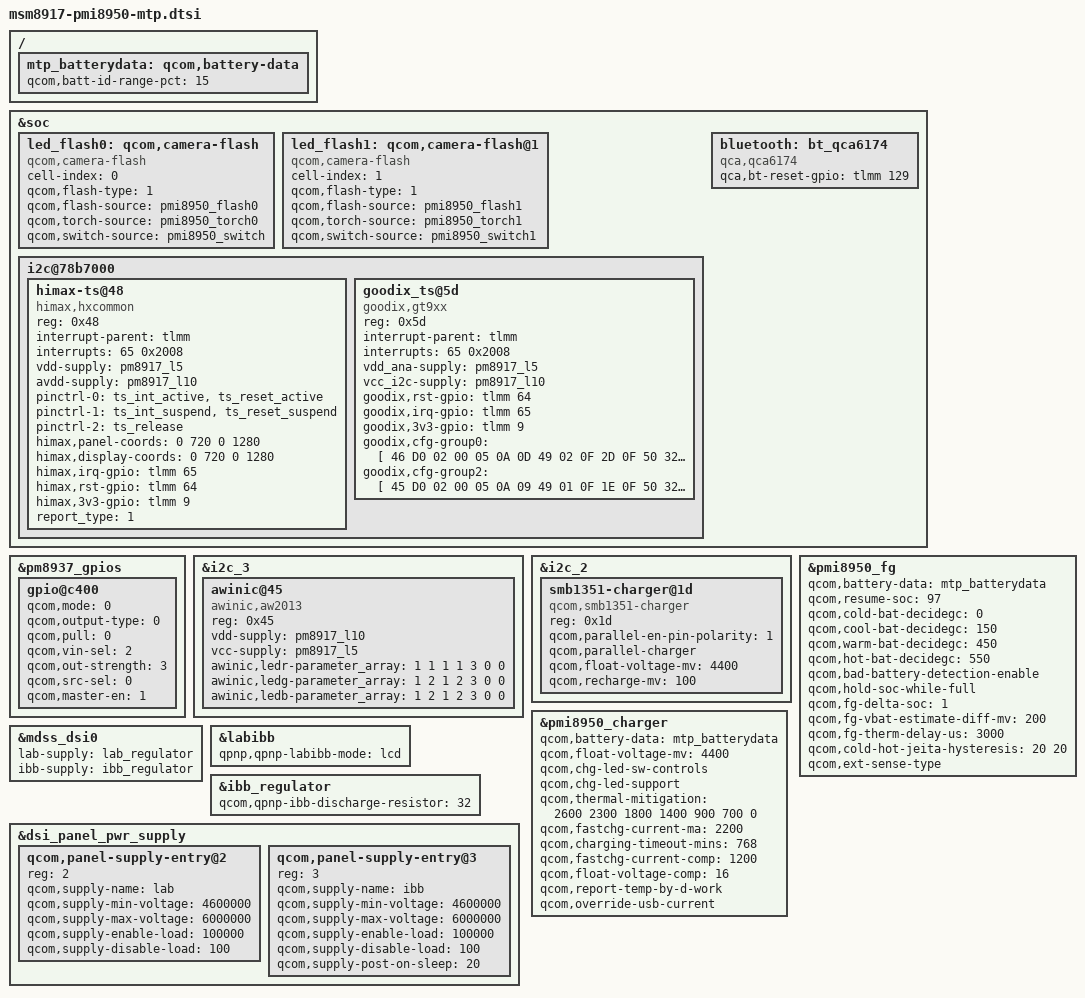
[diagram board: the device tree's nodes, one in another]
/*
 * Copyright (c) 2015-2017, The Linux Foundation. All rights reserved.
 *
 * This program is free software; you can redistribute it and/or modify
 * it under the terms of the GNU General Public License version 2 and
 * only version 2 as published by the Free Software Foundation.
 *
 * This program is distributed in the hope that it will be useful,
 * but WITHOUT ANY WARRANTY; without even the implied warranty of
 * MERCHANTABILITY or FITNESS FOR A PARTICULAR PURPOSE.  See the
 * GNU General Public License for more details.
 */

#include "msm-pmi8950.dtsi"
#include "msm8917-mtp.dtsi"
#include "msm8917-audio-mtp.dtsi"

&soc {
	led_flash0: qcom,camera-flash {
		cell-index = <0>;
		compatible = "qcom,camera-flash";
		qcom,flash-type = <1>;
		qcom,flash-source = <&pmi8950_flash0>;
		qcom,torch-source = <&pmi8950_torch0>;
		qcom,switch-source = <&pmi8950_switch>;
	};

    led_flash1: qcom,camera-flash@1 {
        cell-index = <1>;
        compatible = "qcom,camera-flash";
        qcom,flash-type = <1>;
        qcom,flash-source = <&pmi8950_flash1>;
        qcom,torch-source = <&pmi8950_torch1>;
        qcom,switch-source = <&pmi8950_switch1>;
    };

	i2c@78b7000 {
		status = "ok";
		himax-ts@48 {
			compatible = "himax,hxcommon";
			reg = <0x48>;
			interrupt-parent = <&tlmm>;
			interrupts = <65 0x2008>;
			vdd-supply = <&pm8917_l5>;
			avdd-supply = <&pm8917_l10>;
			pinctrl-names = "pmx_ts_active","pmx_ts_suspend",
				"pmx_ts_release";
			pinctrl-0 = <&ts_int_active &ts_reset_active>;
			pinctrl-1 = <&ts_int_suspend &ts_reset_suspend>;
			pinctrl-2 = <&ts_release>;
			himax,panel-coords   	= <0 720 0 1280>;
			himax,display-coords 	= <0 720 0 1280>;
			himax,irq-gpio       	= <&tlmm 65 0x00>;
			himax,rst-gpio       	= <&tlmm 64 0x00>;
			himax,3v3-gpio      	= <&tlmm 9 0x00>;
			report_type             = <1>;
		};
		goodix_ts@5d {
			compatible = "goodix,gt9xx";
			reg = <0x5d>;
			interrupt-parent = <&tlmm>;
			interrupts = <65 0x2008>;
			vdd_ana-supply = <&pm8917_l5>;
			vcc_i2c-supply = <&pm8917_l10>;
			goodix,rst-gpio = <&tlmm 64 0x00>;
			goodix,irq-gpio = <&tlmm 65 0x00>;
			goodix,3v3-gpio = <&tlmm 9 0x00>;
			goodix,cfg-group0 = [
				46 D0 02 00 05 0A 0D 49 02 0F
				2D 0F 50 32 03 00 00 00 00 00
				00 00 04 18 18 20 14 87 27 CD
				40 3E 09 06 BB 0A 01 1B 33 11
				05 32 0A 03 32 00 40 32 FA A0
				43 28 5A 85 C0 C5 01 1E 00 04
				B0 2B 00 97 33 00 83 3C 00 73
				46 00 64 53 00 64 18 38 60 00
				F0 50 50 FF FF 17 00 91 09 03
				61 6B 03 50 FF 67 00 33 00 28
				00 00 00 00 00 01 50 57 61 03
				50 28 00 01 02 03 04 05 06 07
				08 09 0A 0B 18 17 16 15 14 13
				12 11 10 0F 0E 0D 0C FF FF FF
				FF FF 29 28 24 22 20 1F 1E 0A
				08 06 05 04 02 00 FF FF FF 00
				00 00 00 00 00 00 00 00 00 00
				00 00 00 00 07 00 00 00 88 20
				02 00 00 00 00 00 00 00 00 00
				28 50 00 00 00 00 00 00 00 00
				00 00 00 00 00 00 00 00 00 00
				00 00 00 00 00 00 00 00 00 00
				00 00 00 00 00 00 B6 01];
			goodix,cfg-group2 = [
				45 D0 02 00 05 0A 09 49 01 0F 
				1E 0F 50 32 03 00 00 00 00 00 
				00 00 04 18 18 20 14 87 27 CD 
				69 67 97 05 BB 0A 00 1A 33 11 
				05 32 0A 03 32 00 00 32 FA A0 
				43 4B 7D 85 C0 C5 01 1E 00 04 
				A0 4F 00 93 57 00 87 60 00 7C 
				6B 00 72 76 00 72 18 38 60 00 
				F0 50 50 FF FF 17 00 91 02 03 
				61 6B 03 50 FF 67 00 33 00 28 
				00 00 00 00 00 01 50 57 61 03 
				50 28 00 01 02 03 04 05 06 07 
				08 09 0A 0B 18 17 16 15 14 13 
				12 11 10 0F 0E 0D 0C FF FF FF 
				FF FF 29 28 24 22 20 1F 1E 0A 
				08 06 05 04 02 00 FF FF FF 00 
				00 00 00 00 00 00 00 00 00 00 
				00 00 00 00 07 00 00 00 88 20 
				02 00 00 00 00 00 00 00 00 00 
				00 00 00 00 00 00 00 00 00 00 
				00 00 00 00 00 00 00 00 00 00 
				00 00 00 00 00 00 00 00 00 00 
				00 00 00 00 00 00 9E 01]; 
		};
	};
	
	bluetooth: bt_qca6174 {
		compatible = "qca,qca6174";
		qca,bt-reset-gpio = <&tlmm 129 0>; /* BT_EN */
	};
};

/{
	mtp_batterydata: qcom,battery-data {
		qcom,batt-id-range-pct = <15>;
		#include "batterydata-qrd-veken-4v4-3000mah.dtsi"
		#include "batterydata-qrd-jiade-4v4-3000mah.dtsi"
	};
};

&pm8937_gpios {
	gpio@c400 {
		qcom,mode = <0>;
		qcom,output-type = <0>;
		qcom,pull = <0>;
		qcom,vin-sel = <2>;
		qcom,out-strength = <3>;
		qcom,src-sel = <0>;
		qcom,master-en = <1>;
		status = "okay";
	};
};

&i2c_3 { /* BLSP2 QUP1 */
	awinic@45 { /* Breath Light-Driven */
		compatible = "awinic,aw2013";
		reg = <0x45>;
		vdd-supply = <&pm8917_l10>;
		vcc-supply = <&pm8917_l5>;
		awinic,ledr-parameter_array = <1 1 1 1 3 0 0>; //12121
		awinic,ledg-parameter_array = <1 2 1 2 3 0 0>;
		awinic,ledb-parameter_array = <1 2 1 2 3 0 0>;
	};
};

&i2c_2 {
	//Parallel-charger configuration
	smb1351-charger@1d {
		compatible = "qcom,smb1351-charger";
		reg = <0x1d>;
		qcom,parallel-en-pin-polarity = <1>;
		qcom,parallel-charger;
		qcom,float-voltage-mv = <4400>;
		qcom,recharge-mv = <100>;
	};
};

&pmi8950_fg {
	qcom,battery-data = <&mtp_batterydata>;
	qcom,resume-soc = <97>;
	qcom,cold-bat-decidegc = <0>;
	qcom,cool-bat-decidegc = <150>;
	qcom,warm-bat-decidegc = <450>;
	qcom,hot-bat-decidegc = <550>;
	qcom,bad-battery-detection-enable;
	qcom,hold-soc-while-full;
	qcom,fg-delta-soc = <1>;
	qcom,fg-vbat-estimate-diff-mv = <200>;
	qcom,fg-therm-delay-us = <3000>;
	qcom,cold-hot-jeita-hysteresis = <20 20>;
	qcom,ext-sense-type;
};

&pmi8950_charger {
	qcom,battery-data = <&mtp_batterydata>;
	qcom,float-voltage-mv = <4400>;
	qcom,chg-led-sw-controls;
	qcom,chg-led-support;
        qcom,thermal-mitigation = <2600 2300 1800 1400 900 700 0>;
	qcom,fastchg-current-ma = <2200>;
	qcom,charging-timeout-mins = <768>;
	qcom,fastchg-current-comp = <1200>;
	/* 11 for 4.2V, 16 for 4.1V */
	qcom,float-voltage-comp = <16>;
	qcom,report-temp-by-d-work;
        qcom,override-usb-current;
	status = "okay";
};

&mdss_dsi0 {
	lab-supply = <&lab_regulator>;
	ibb-supply = <&ibb_regulator>;
};

&labibb {
	status = "ok";
	qpnp,qpnp-labibb-mode = "lcd";
};

&ibb_regulator {
	qcom,qpnp-ibb-discharge-resistor = <32>;
};

&dsi_panel_pwr_supply {
	qcom,panel-supply-entry@2 {
		reg = <2>;
		qcom,supply-name = "lab";
		qcom,supply-min-voltage = <4600000>;
		qcom,supply-max-voltage = <6000000>;
		qcom,supply-enable-load = <100000>;
		qcom,supply-disable-load = <100>;
	};

	qcom,panel-supply-entry@3 {
		reg = <3>;
		qcom,supply-name = "ibb";
		qcom,supply-min-voltage = <4600000>;
		qcom,supply-max-voltage = <6000000>;
		qcom,supply-enable-load = <100000>;
		qcom,supply-disable-load = <100>;
		qcom,supply-post-on-sleep = <20>;
	};
};
